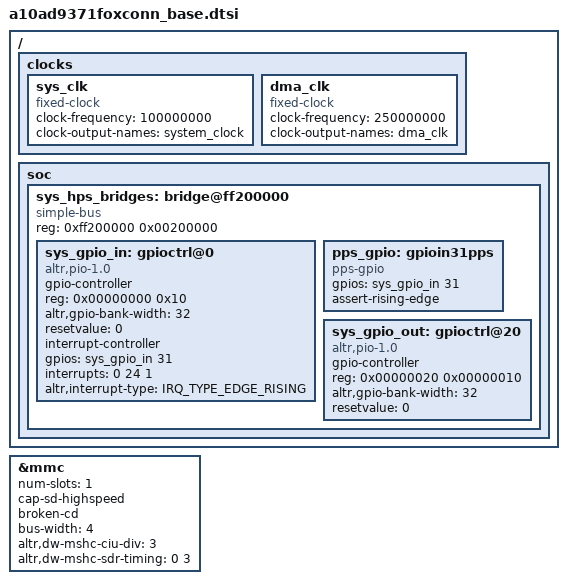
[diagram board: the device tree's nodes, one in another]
#include "socfpga_arria10_socdk.dtsi"

&mmc {
	status = "okay";
	num-slots = <1>;
	cap-sd-highspeed;
	broken-cd;
	bus-width = <4>;
	altr,dw-mshc-ciu-div = <3>;
	altr,dw-mshc-sdr-timing = <0 3>;
};

/ {
	clocks {
		sys_clk: sys_clk {
			#clock-cells = <0>;
			compatible = "fixed-clock";
			clock-frequency = <100000000>;
			clock-output-names = "system_clock";
		};

		dma_clk: dma_clk {
			#clock-cells = <0x0>;
			compatible = "fixed-clock";
			clock-frequency = <250000000>;
			clock-output-names = "dma_clk";
		};
	};

	soc {
		sys_hps_bridges: bridge@ff200000 {
			compatible = "simple-bus";
			reg = <0xff200000 0x00200000>;
			#address-cells = <1>;
			#size-cells = <1>;
			ranges = <0x00000000 0xff200000 0x00200000>;

			/* Documentation/devicetree/bindings/interrupt-controller/arm,gic.txt */
			/* Documentation/devicetree/bindings/gpio/gpio-altera.txt */
			sys_gpio_in: gpioctrl@0 {
	   			gpio-controller;
	   			reg = <0x00000000 0x10>;
				altr,gpio-bank-width = <32>;
				resetvalue = <0>;
	   			#gpio-cells = <2>;
	   			compatible = "altr,pio-1.0";

				/* gpioin31irq */
	   			interrupt-controller;
				gpios = <&sys_gpio_in 31 0>;
				/* irq-type irq-number low-to-high-edge */
				/* irq-number = 24(FPGA_IRQ_BASE) + specific irq vector */
	   			interrupts = <0 24 1>;
	   			#interrupt-cells = <1>;
	   			altr,interrupt-type = <IRQ_TYPE_EDGE_RISING>;
			};

			/* Documentation/devicetree/bindings/pps/pps-gpio.txt  */
			pps_gpio: gpioin31pps {
				compatible = "pps-gpio";
				gpios = <&sys_gpio_in 31 0>;
				/* comment means assert is indicated by a rising edge */
				assert-rising-edge;
			};

			sys_gpio_out: gpioctrl@20 {
				gpio-controller;
				reg = <0x00000020 0x00000010>;
				altr,gpio-bank-width = <32>;
				resetvalue = <0>;
				#gpio-cells = <2>;
				compatible = "altr,pio-1.0";
			};
		};
	};
};
